# M4G9 register map
File version: 0.1
TOSHIBA Cortex-M4 MCU
Registers are 32-bit, read-write, reset 0x0 unless marked. A register's access mark holds for its fields unless they carry their own. Offsets are from the block's base; lines under a group give offsets from that group; [hi:lo] are bit positions; {n}, {i} and the like mark numbered series; 'fields as' and 'values as' point back to an identical list; <NAME> marks a mode.

## Memory map
0x40000000 DMACA blocks up to offset 0x134 — DMA Controller
0x40001000 DMACB blocks up to offset 0x134
0x4000C000 SMI blocks up to offset 0x700
0x4003E000 IA blocks up to offset 0x5A — Interrupt control A Register
0x4003E400 RLM blocks up to offset 0x10 — Reset Low power Managiment Register
0x4003EC00 LVD size 0x5 — LVD0
0x4003FF00 LTT size 0x3 — Long Term Timer(LTTMR)
0x4006A000 TSPI0 blocks up to offset 0x208 — Serial Interface (TSPI)
0x4006A400 TSPI1 blocks up to offset 0x208
0x4006A800 TSPI2 blocks up to offset 0x208
0x4006AC00 TSPI3 blocks up to offset 0x208
0x4006B000 TSPI4 blocks up to offset 0x208
0x4006B400 TSPI5 blocks up to offset 0x208
0x40076000 EXB blocks up to offset 0x64 — External Bus Interface(EXB)
0x40083000 CG blocks up to offset 0x6C — Clock Generator (CG)
0x40083200 IB blocks up to offset 0xEE — Interrupt Control B Register
0x40083300 IMN size 0x20 — Interrupt Monitor Register
0x400A0200 DNFA size 0x8 — DNF
0x400A0300 DNFB size 0x8
0x400A0400 TSEL size 0x38 — TRGSEL
0x400A0600 SIWD size 0x14 — Watchdog Timer (WD)
0x400A2000 NBD size 0x8
0x400A4000 MDMA blocks up to offset 0x804 — Malti Porpose Direct Memory Accsess(MDMA)
0x400A8000 FURT0 blocks up to offset 0x4C — ARM Prime Cell PL011
0x400A9000 FURT1 blocks up to offset 0x4C
0x400BA000 AD blocks up to offset 0x1A0 — ADC
0x400BC800 DA0 size 0x8 — Digital analog converter (DAC)
0x400BC900 DA1 size 0x8
0x400C1000 T32A0 blocks up to offset 0xFC — 16-bit Timer_Event Counter (TB)
{0x400C1000+0x400*n} T32A{n} blocks up to offset 0xFC (n=1..13)
0x400CB800 TSPI6 blocks up to offset 0x208
0x400CBC00 TSPI7 blocks up to offset 0x208
0x400CC000 TSPI8 blocks up to offset 0x208
0x400CE000 UART0 size 0x28 — UART
0x400CE400 UART1 size 0x28
0x400CE800 UART2 size 0x28
0x400CEC00 UART3 size 0x28
0x400CF000 UART4 size 0x28
0x400CF400 UART5 size 0x28
0x400D1000 I2C0 size 0x28 — I2C
0x400D2000 I2C1 size 0x28
0x400D3000 I2C2 size 0x28
0x400D4000 I2C3 size 0x28
0x400D5000 I2C4 size 0x28
0x400E0000 PA blocks up to offset 0x3C — Port A
0x400E0100 PB blocks up to offset 0x3C — Port B
0x400E0200 PC blocks up to offset 0x3C — Port C
0x400E0300 PD blocks up to offset 0x3C — Port D
0x400E0400 PE blocks up to offset 0x3C — Port E
0x400E0500 PF blocks up to offset 0x3C — Port F
0x400E0600 PG blocks up to offset 0x3C — Port G
0x400E0700 PH blocks up to offset 0x3C — Port H
0x400E0800 PJ blocks up to offset 0x3C — Port J
0x400E0900 PK blocks up to offset 0x3C — Port K
0x400E0A00 PL blocks up to offset 0x3C — Port L
0x400E0B00 PM blocks up to offset 0x3C — Port M
0x400E0C00 PN blocks up to offset 0x3C — Port N
0x400E0D00 PP blocks up to offset 0x3C — Port P
0x400E0E00 PR blocks up to offset 0x3C — Port R
0x400E0F00 PT blocks up to offset 0x3C — Port T
0x400E1000 PU blocks up to offset 0x3C — Port U
0x400E1100 PV blocks up to offset 0x3C — Port V
0x400E1200 PW blocks up to offset 0x3C — Port W
0x400E1300 PY blocks up to offset 0x3C — Port Y
0x400E3100 TRMOSC size 0x10 — Internal High-speed Oscillation Adjustment
0x400E4000 OFD size 0x24 — Oscillation Frequency Detector (OFD)
0x400E4800 RTC blocks up to offset 0x12 — Real Time Clock (RTC)
0x400E8000 CEC size 0x38 — Consumer Electronics Control (CEC)
0x400E8100 RMC0 size 0x38 — Remote Control Signal Preprocessor (RMC)
0x400E8200 RMC1 size 0x38
0x400E9000 PMD size 0x7C
0x400F0000 SDA size 0x24 — SD
0x400F0100 SDB size 0x24
0x400F0200 SDC size 0x24
0x5DFF0000 FC blocks up to offset 0x15C

## DMACA — DMA Controller
Base 0x40000000
Same registers: DMACB 0x40001000
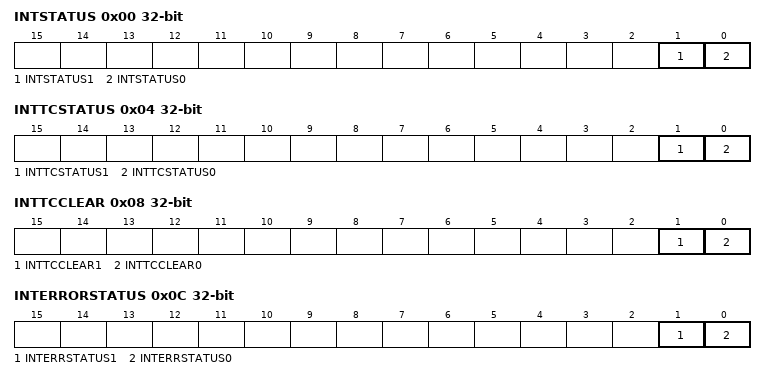
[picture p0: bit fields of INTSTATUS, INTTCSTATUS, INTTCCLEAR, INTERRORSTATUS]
0x00 INTSTATUS ro — DMAC Interrupt Status Register
  [1] INTSTATUS1, [0] INTSTATUS0
0x04 INTTCSTATUS ro — DMAC Interrupt Terminal Count Status Register
  [1] INTTCSTATUS1, [0] INTTCSTATUS0
0x08 INTTCCLEAR wo — DMAC Interrupt Terminal Count Clear Register
  [1] INTTCCLEAR1, [0] INTTCCLEAR0
0x0C INTERRORSTATUS ro — DMAC Interrupt Error Status Register
  [1] INTERRSTATUS1, [0] INTERRSTATUS0
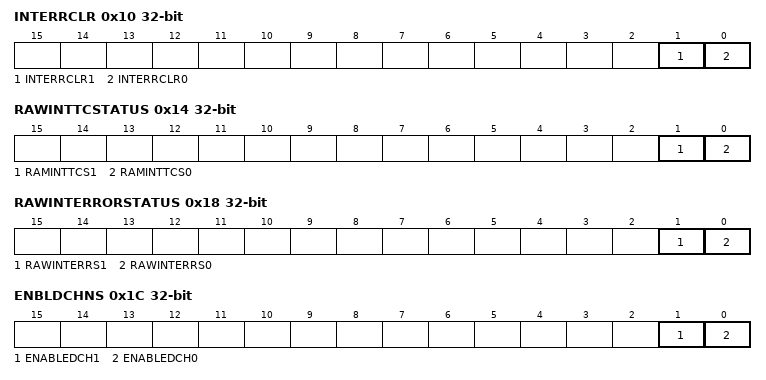
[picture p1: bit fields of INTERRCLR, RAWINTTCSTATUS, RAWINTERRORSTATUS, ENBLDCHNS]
0x10 INTERRCLR wo — DMAC Interrupt Error Clear Register
  [1] INTERRCLR1, [0] INTERRCLR0
0x14 RAWINTTCSTATUS ro — DMAC Raw Interrupt Terminal Count Status Register
  [1] RAMINTTCS1, [0] RAMINTTCS0
0x18 RAWINTERRORSTATUS ro — DMAC Raw Error Interrupt Status Register
  [1] RAWINTERRS1, [0] RAWINTERRS0
0x1C ENBLDCHNS ro — DMAC Enabled Channel Register
  [1] ENABLEDCH1, [0] ENABLEDCH0
0x20 SOFTBREQ — DMAC Software Burst Request Register
  [15:0] SOFTBREQ
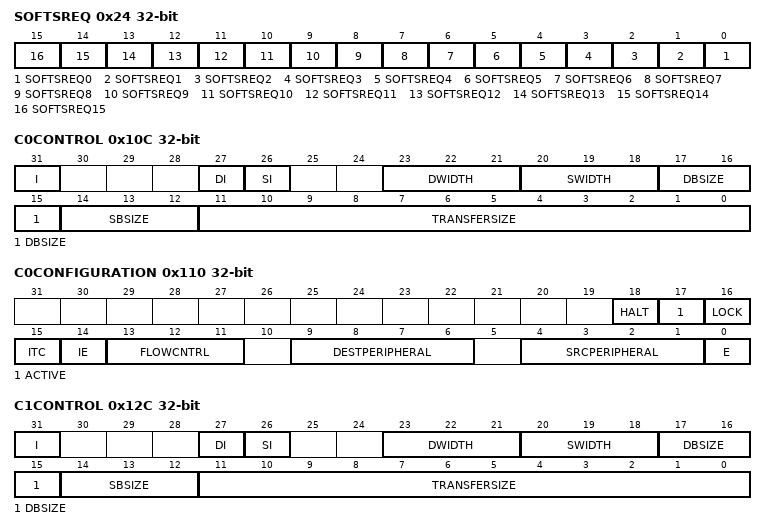
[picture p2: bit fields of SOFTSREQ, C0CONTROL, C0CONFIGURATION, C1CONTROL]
0x24 SOFTSREQ — DMAC Software Single Request Register
  [n] SOFTSREQ{n} (n=0..15)
0x30 CONFIGURATION — DMAC Configuration Register
  [0] E
0x100 C0SRCADDR — DMAC Channel 0 Source Address Register
  [31:0] SRCADDR
0x104 C0DESTADDR — DMAC Channel 0 Destination Address Register
  [31:0] DESTADDR
0x108 C0LLI — DMAC Channel 0 Linked List Item Register
  [31:2] LLI
0x10C C0CONTROL — DMAC Channel 0 Control Register
  [31] I, [27] DI, [26] SI, [23:21] DWIDTH, [20:18] SWIDTH, [17:15] DBSIZE, [14:12] SBSIZE, [11:0] TRANSFERSIZE
0x110 C0CONFIGURATION (reset mask 0x7FBDE) — DMAC Channel 0 Configuration Register
  [18] HALT, [17] ACTIVE ro, [16] LOCK, [15] ITC, [14] IE, [13:11] FLOWCNTRL, [9:6] DESTPERIPHERAL, [4:1] SRCPERIPHERAL, [0] E
0x120 C1SRCADDR — DMAC Channel 1 Source Address Register
  [31:0] SRCADDR
0x124 C1DESTADDR — DMAC Channel 1 Destination Address Register
  [31:0] DESTADDR
0x128 C1LLI — DMAC Channel 1 Linked List Item Register
  [31:2] LLI
0x12C C1CONTROL — DMAC Channel 1 Control Register
  fields as C0CONTROL
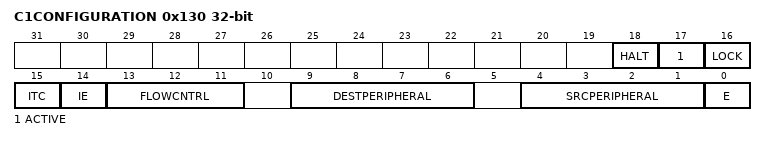
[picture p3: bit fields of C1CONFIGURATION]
0x130 C1CONFIGURATION (reset mask 0x7FBDE) — DMAC Channel 1 Configuration Register
  fields as C0CONFIGURATION
